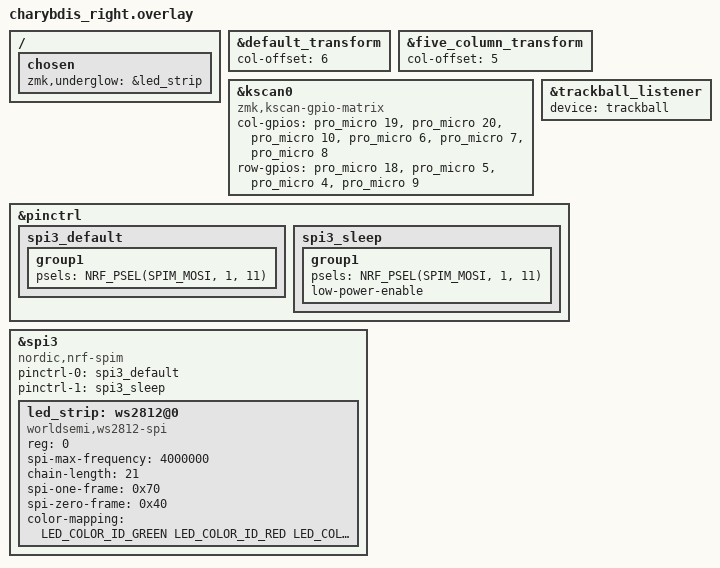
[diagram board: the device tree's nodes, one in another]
#include "charybdis.dtsi"
#include "charybdis_pmw3610.dtsi"
#include "charybdis_pointer.dtsi"

// The matrix transform is 6 columns over because the left half is 6 columns wide.
&default_transform {
	col-offset = <6>;
};

&five_column_transform {
	col-offset = <5>;
};

// KSCAN matrix
&kscan0 {
	compatible = "zmk,kscan-gpio-matrix";
	
	col-gpios
		= <&pro_micro 19 (GPIO_ACTIVE_HIGH | GPIO_PULL_DOWN)>
		, <&pro_micro 20 (GPIO_ACTIVE_HIGH | GPIO_PULL_DOWN)>
		, <&pro_micro 10 (GPIO_ACTIVE_HIGH | GPIO_PULL_DOWN)>
		, <&pro_micro 6 (GPIO_ACTIVE_HIGH | GPIO_PULL_DOWN)>
		, <&pro_micro 7 (GPIO_ACTIVE_HIGH | GPIO_PULL_DOWN)>
		, <&pro_micro 8 (GPIO_ACTIVE_HIGH | GPIO_PULL_DOWN)>
		;

	row-gpios
		= <&pro_micro 18 GPIO_ACTIVE_HIGH>
		, <&pro_micro 5 GPIO_ACTIVE_HIGH>
		, <&pro_micro 4 GPIO_ACTIVE_HIGH>
		, <&pro_micro 9 GPIO_ACTIVE_HIGH>
		;
};

/* enable the listener on central */
&trackball_listener {
    status = "okay";
    device = <&trackball>;
};


// Underglow Lighting Settings (Right)

#include <dt-bindings/led/led.h>

&pinctrl {
    spi3_default: spi3_default {
        group1 {
            psels = <NRF_PSEL(SPIM_MOSI, 1, 11)>;
        };
    };

    spi3_sleep: spi3_sleep {
        group1 {
            psels = <NRF_PSEL(SPIM_MOSI, 1, 11)>;
            low-power-enable;
        };
    };
};

&spi3 {
    compatible = "nordic,nrf-spim";
    status = "okay";

    pinctrl-0 = <&spi3_default>;
    pinctrl-1 = <&spi3_sleep>;
    pinctrl-names = "default", "sleep";

    led_strip: ws2812@0 {
        compatible = "worldsemi,ws2812-spi";

        /* SPI */
        reg = <0>; /* ignored, but necessary for SPI bindings */
        spi-max-frequency = <4000000>;

        /* WS2812 */
        chain-length = <21>; /* arbitrary; change at will */
        spi-one-frame = <0x70>;
        spi-zero-frame = <0x40>;

        color-mapping = <LED_COLOR_ID_GREEN LED_COLOR_ID_RED LED_COLOR_ID_BLUE>;
    };
};

/ {
    chosen {
        zmk,underglow = &led_strip;
    };
};
